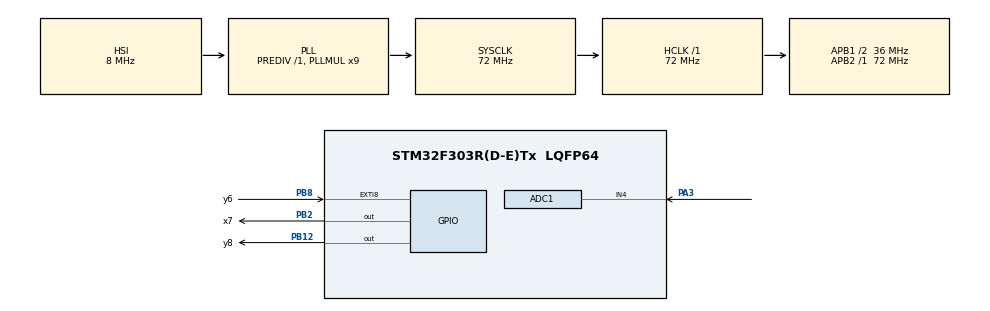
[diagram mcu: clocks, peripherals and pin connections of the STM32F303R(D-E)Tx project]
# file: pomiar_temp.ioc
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ADC1.Channel-0\#ChannelRegularConversion=ADC_CHANNEL_TEMPSENSOR
ADC1.ClockPrescaler=ADC_CLOCK_SYNC_PCLK_DIV4
ADC1.ContinuousConvMode=ENABLE
ADC1.NbrOfConversionFlag=1
ADC1.Offset-0\#ChannelRegularConversion=0
ADC1.OffsetNumber-0\#ChannelRegularConversion=ADC_OFFSET_NONE
ADC1.Rank-0\#ChannelRegularConversion=1
ADC1.SamplingTime-0\#ChannelRegularConversion=ADC_SAMPLETIME_601CYCLES_5
ADC1.master=1
Mcu.Family=STM32F3
Mcu.Name=STM32F303R(D-E)Tx
Mcu.Package=LQFP64
NVIC.ADC1_2_IRQn=true\:0\:0\:false\:false\:true\:true
NVIC.EXTI9_5_IRQn=true\:0\:0\:false\:true\:true\:1\:true
NVIC.PriorityGroup=NVIC_PRIORITYGROUP_4
PA3.Mode=IN4-Single-Ended
PA3.Signal=ADC1_IN4
PB12.GPIO_Label=y8
PB12.Signal=GPIO_Output
PB2.GPIO_Label=x7
PB2.Signal=GPIO_Output
PB8.GPIO_Label=y6
PB8.GPIO_ModeDefaultEXTI=GPIO_MODE_IT_RISING_FALLING
PB8.Signal=GPXTI8
ProjectManager.HeapSize=0x200
ProjectManager.StackSize=0x400
ProjectManager.TargetToolchain=TrueSTUDIO
RCC.AHBFreq_Value=72000000
RCC.APB1CLKDivider=RCC_HCLK_DIV2
RCC.APB1Freq_Value=36000000
RCC.APB1TimFreq_Value=72000000
RCC.APB2Freq_Value=72000000
RCC.APB2TimFreq_Value=72000000
RCC.CortexFreq_Value=72000000
RCC.HCLKFreq_Value=72000000
RCC.HSE_VALUE=8000000
RCC.HSI_VALUE=8000000
RCC.LSE_VALUE=32768
RCC.PLLMUL=RCC_PLL_MUL9
RCC.SYSCLKFreq_VALUE=72000000
RCC.SYSCLKSourceVirtual=RCC_SYSCLKSOURCE_PLLCLK
RCC.USBFreq_Value=72000000
VP_ADC1_TempSens_Input.Mode=IN-TempSens
board=pomiar_temp

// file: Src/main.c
/**
  ******************************************************************************
  * @file           : main.c
  * @brief          : Main program body
  ******************************************************************************
  ** This notice applies to any and all portions of this file
  * that are not between comment pairs USER CODE BEGIN and
  * USER CODE END. Other portions of this file, whether
  * inserted by the user or by software development tools
  * are owned by their respective copyright owners.
  *
  * COPYRIGHT(c) 2019 STMicroelectronics
  *
  * Redistribution and use in source and binary forms, with or without modification,
  * are permitted provided that the following conditions are met:
  *   1. Redistributions of source code must retain the above copyright notice,
  *      this list of conditions and the following disclaimer.
  *   2. Redistributions in binary form must reproduce the above copyright notice,
  *      this list of conditions and the following disclaimer in the documentation
  *      and/or other materials provided with the distribution.
  *   3. Neither the name of STMicroelectronics nor the names of its contributors
  *      may be used to endorse or promote products derived from this software
  *      without specific prior written permission.
  *
  * THIS SOFTWARE IS PROVIDED BY THE COPYRIGHT HOLDERS AND CONTRIBUTORS "AS IS"
  * AND ANY EXPRESS OR IMPLIED WARRANTIES, INCLUDING, BUT NOT LIMITED TO, THE
  * IMPLIED WARRANTIES OF MERCHANTABILITY AND FITNESS FOR A PARTICULAR PURPOSE ARE
  * DISCLAIMED. IN NO EVENT SHALL THE COPYRIGHT HOLDER OR CONTRIBUTORS BE LIABLE
  * FOR ANY DIRECT, INDIRECT, INCIDENTAL, SPECIAL, EXEMPLARY, OR CONSEQUENTIAL
  * DAMAGES (INCLUDING, BUT NOT LIMITED TO, PROCUREMENT OF SUBSTITUTE GOODS OR
  * SERVICES; LOSS OF USE, DATA, OR PROFITS; OR BUSINESS INTERRUPTION) HOWEVER
  * CAUSED AND ON ANY THEORY OF LIABILITY, WHETHER IN CONTRACT, STRICT LIABILITY,
  * OR TORT (INCLUDING NEGLIGENCE OR OTHERWISE) ARISING IN ANY WAY OUT OF THE USE
  * OF THIS SOFTWARE, EVEN IF ADVISED OF THE POSSIBILITY OF SUCH DAMAGE.
  *
  ******************************************************************************
  */
#include "main.h"
#include "stm32f3xx_hal.h"

ADC_HandleTypeDef hadc1;

/* USER CODE BEGIN PV */
/* Private variables ---------------------------------------------------------*/
uint16_t PomiarADC;
float Temperature;
float Vsense;

const float V25 = 0.76; // [Volts]
const float Avg_slope = 0.0025; //[Volts/degree]
const float SupplyVoltage = 3.0; // [Volts]
const float ADCResolution = 4096.0;
/* USER CODE END PV */

void SystemClock_Config(void);
static void MX_GPIO_Init(void);
static void MX_DMA_Init(void);
static void MX_ADC1_Init(void);

/* USER CODE BEGIN PFP */
/* Private function prototypes -----------------------------------------------*/

void HAL_ADC_ConvCpltCallback(ADC_HandleTypeDef* hadc){
 PomiarADC = HAL_ADC_GetValue(&hadc1); // Pobranie zmierzonej wartosci
 Vsense = (SupplyVoltage*PomiarADC)/(ADCResolution-1); // Przeliczenie wartosci zmierzonej na napiecie
 Temperature = ((Vsense-V25)/Avg_slope)+25; // Obliczenie temperatury
}
/* USER CODE END PFP */

int main(void)
{

  /* MCU Configuration----------------------------------------------------------*/

  /* Reset of all peripherals, Initializes the Flash interface and the Systick. */
  HAL_Init();

  /* Configure the system clock */
  SystemClock_Config();

  /* Initialize all configured peripherals */
  MX_GPIO_Init();
  MX_ADC1_Init();

  /* Initialize interrupts */
  MX_NVIC_Init();

  /* Infinite loop */
  while (1)
  {

  }

}

void SystemClock_Config(void)
{

  RCC_OscInitTypeDef RCC_OscInitStruct;
  RCC_ClkInitTypeDef RCC_ClkInitStruct;

    /**Initializes the CPU, AHB and APB busses clocks
    */
  RCC_OscInitStruct.OscillatorType = RCC_OSCILLATORTYPE_HSI;
  RCC_OscInitStruct.HSIState = RCC_HSI_ON;
  RCC_OscInitStruct.HSICalibrationValue = 16;
  RCC_OscInitStruct.PLL.PLLState = RCC_PLL_ON;
  RCC_OscInitStruct.PLL.PLLSource = RCC_PLLSOURCE_HSI;
  RCC_OscInitStruct.PLL.PLLMUL = RCC_PLL_MUL9;
  RCC_OscInitStruct.PLL.PREDIV = RCC_PREDIV_DIV1;
  if (HAL_RCC_OscConfig(&RCC_OscInitStruct) != HAL_OK)
  {
    _Error_Handler(__FILE__, __LINE__);
  }

    /**Initializes the CPU, AHB and APB busses clocks
    */
  RCC_ClkInitStruct.ClockType = RCC_CLOCKTYPE_HCLK|RCC_CLOCKTYPE_SYSCLK
                              |RCC_CLOCKTYPE_PCLK1|RCC_CLOCKTYPE_PCLK2;
  RCC_ClkInitStruct.SYSCLKSource = RCC_SYSCLKSOURCE_PLLCLK;
  RCC_ClkInitStruct.AHBCLKDivider = RCC_SYSCLK_DIV1;
  RCC_ClkInitStruct.APB1CLKDivider = RCC_HCLK_DIV2;
  RCC_ClkInitStruct.APB2CLKDivider = RCC_HCLK_DIV1;

  if (HAL_RCC_ClockConfig(&RCC_ClkInitStruct, FLASH_LATENCY_2) != HAL_OK)
  {
    _Error_Handler(__FILE__, __LINE__);
  }

    /**Configure the Systick interrupt time
    */
  HAL_SYSTICK_Config(HAL_RCC_GetHCLKFreq()/1000);

    /**Configure the Systick
    */
  HAL_SYSTICK_CLKSourceConfig(SYSTICK_CLKSOURCE_HCLK);

  /* SysTick_IRQn interrupt configuration */
  HAL_NVIC_SetPriority(SysTick_IRQn, 0, 0);
}

/**
  * @brief NVIC Configuration.
  * @retval None
  */
static void MX_NVIC_Init(void)
{
  /* EXTI9_5_IRQn interrupt configuration */
  HAL_NVIC_SetPriority(EXTI9_5_IRQn, 0, 0);
  HAL_NVIC_EnableIRQ(EXTI9_5_IRQn);
}

/* ADC1 init function */
static void MX_ADC1_Init(void)
{

  ADC_MultiModeTypeDef multimode;
  ADC_ChannelConfTypeDef sConfig;

    /**Common config
    */
  hadc1.Instance = ADC1;
  hadc1.Init.ClockPrescaler = ADC_CLOCK_SYNC_PCLK_DIV4;
  hadc1.Init.Resolution = ADC_RESOLUTION_12B;
  hadc1.Init.ScanConvMode = ADC_SCAN_DISABLE;
  hadc1.Init.ContinuousConvMode = ENABLE;
  hadc1.Init.DiscontinuousConvMode = DISABLE;
  hadc1.Init.ExternalTrigConvEdge = ADC_EXTERNALTRIGCONVEDGE_NONE;
  hadc1.Init.ExternalTrigConv = ADC_SOFTWARE_START;
  hadc1.Init.DataAlign = ADC_DATAALIGN_RIGHT;
  hadc1.Init.NbrOfConversion = 1;
  hadc1.Init.DMAContinuousRequests = DISABLE;
  hadc1.Init.EOCSelection = ADC_EOC_SINGLE_CONV;
  hadc1.Init.LowPowerAutoWait = DISABLE;
  hadc1.Init.Overrun = ADC_OVR_DATA_OVERWRITTEN;
  if (HAL_ADC_Init(&hadc1) != HAL_OK)
  {
    _Error_Handler(__FILE__, __LINE__);
  }

    /**Configure the ADC multi-mode
    */
  multimode.Mode = ADC_MODE_INDEPENDENT;
  if (HAL_ADCEx_MultiModeConfigChannel(&hadc1, &multimode) != HAL_OK)
  {
    _Error_Handler(__FILE__, __LINE__);
  }

    /**Configure Regular Channel
    */
  sConfig.Channel = ADC_CHANNEL_TEMPSENSOR;
  sConfig.Rank = ADC_REGULAR_RANK_1;
  sConfig.SingleDiff = ADC_SINGLE_ENDED;
  sConfig.SamplingTime = ADC_SAMPLETIME_601CYCLES_5;
  sConfig.OffsetNumber = ADC_OFFSET_NONE;
  sConfig.Offset = 0;
  if (HAL_ADC_ConfigChannel(&hadc1, &sConfig) != HAL_OK)
  {
    _Error_Handler(__FILE__, __LINE__);
  }

}

/** Configure pins as
        * Analog
        * Input
        * Output
        * EVENT_OUT
        * EXTI
*/
static void MX_GPIO_Init(void)
{

  GPIO_InitTypeDef GPIO_InitStruct;

  /* GPIO Ports Clock Enable */
  __HAL_RCC_GPIOA_CLK_ENABLE();
  __HAL_RCC_GPIOB_CLK_ENABLE();

  /*Configure GPIO pin Output Level */
  HAL_GPIO_WritePin(GPIOB, x7_Pin|y8_Pin, GPIO_PIN_RESET);

  /*Configure GPIO pins : x7_Pin y8_Pin */
  GPIO_InitStruct.Pin = x7_Pin|y8_Pin;
  GPIO_InitStruct.Mode = GPIO_MODE_OUTPUT_PP;
  GPIO_InitStruct.Pull = GPIO_NOPULL;
  GPIO_InitStruct.Speed = GPIO_SPEED_FREQ_LOW;
  HAL_GPIO_Init(GPIOB, &GPIO_InitStruct);

  /*Configure GPIO pin : y6_Pin */
  GPIO_InitStruct.Pin = y6_Pin;
  GPIO_InitStruct.Mode = GPIO_MODE_IT_RISING_FALLING;
  GPIO_InitStruct.Pull = GPIO_NOPULL;
  HAL_GPIO_Init(y6_GPIO_Port, &GPIO_InitStruct);

}

void _Error_Handler(char *file, int line)
{
  while(1)
  {
  }
}

/************************ (C) COPYRIGHT STMicroelectronics *****END OF FILE****/
